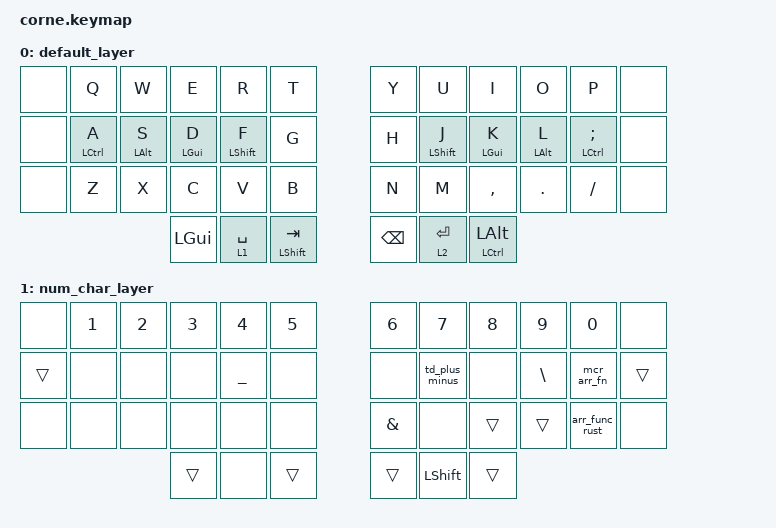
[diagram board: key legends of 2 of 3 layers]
/*
 * Copyright (c) 2020 The ZMK Contributors
 *
 * SPDX-License-Identifier: MIT
 */

#include <behaviors.dtsi>
#include <dt-bindings/zmk/bt.h>
#include <dt-bindings/zmk/keys.h>

&soft_off { hold-time-ms = <200>; };

/ {
    macros {
        mcr_arr_fn: macro_arrow_fn {
            compatible = "zmk,behavior-macro";
            #binding-cells = <0>;
            bindings = <&kp EQUAL &kp GT &kp SPACE &kp LEFT_BRACE &kp RET>;
            label = "MACRO_ARROW_FN";
        };

        mcr_comma_space_cyr: mcr_comma_space {
            compatible = "zmk,behavior-macro";
            #binding-cells = <0>;
            bindings = <&kp CARET &kp SPACE>;
            label = "MCR_COMMA_SPACE";
        };

        mcr_dot_space_cyr: mcr_dot_space {
            compatible = "zmk,behavior-macro";
            #binding-cells = <0>;
            bindings = <&kp AMPERSAND &kp SPACE &skl LEFT_SHIFT>;
            label = "MCR_DOT_SPACE";
        };

        mcr_ctrl_c: ctrl_c {
            compatible = "zmk,behavior-macro";
            #binding-cells = <0>;
            bindings = <&kp LG(C)>;
            label = "CTRL_C";
        };

        mcr_ctrl_v: ctrl_v {
            compatible = "zmk,behavior-macro";
            #binding-cells = <0>;
            bindings = <&kp LG(V)>;
            label = "CTRL_V";
        };

        mcr_switch_language: switch_language {
            compatible = "zmk,behavior-macro";
            #binding-cells = <0>;
            bindings = <&kp LC(SPACE)>;
            label = "SWITCH_LANGUAGE";
        };

        mcr_ctrl_z: mcr_ctrl_z {
            compatible = "zmk,behavior-macro";
            #binding-cells = <0>;
            bindings = <&kp LG(Z)>;
            label = "MCR_CTRL_Z";
        };

        mcr_ctrl_a: mcr_ctrl_a {
            compatible = "zmk,behavior-macro";
            #binding-cells = <0>;
            bindings = <&kp LG(A)>;
            label = "MCR_CTRL_A";
        };

        mcr_fullsize_window: mcr_fullsize_window {
            compatible = "zmk,behavior-macro";
            #binding-cells = <0>;
            bindings = <&kp LG(LC(F))>;
            label = "MCR_FULLSIZE_WINDOW";
        };

        mcr_switch_window_right: mcr_switch_window_right {
            compatible = "zmk,behavior-macro";
            #binding-cells = <0>;
            bindings = <&kp LC(RIGHT)>;
            label = "MCR_SWITCH_WINDOW_RIGHT";
        };

        mcr_switch_window_left: mcr_switch_window_left {
            compatible = "zmk,behavior-macro";
            #binding-cells = <0>;
            bindings = <&kp LC(LEFT)>;
            label = "MCR_SWITCH_WINDOW_LEFT";
        };

        mcr_view_all_windows: mcr_view_all_windows {
            compatible = "zmk,behavior-macro";
            #binding-cells = <0>;
            bindings = <&kp LC(UP_ARROW)>;
            label = "MCR_VIEW_ALL_WINDOWS";
        };

        mcr_screenshot: mcr_screenshot {
            compatible = "zmk,behavior-macro";
            #binding-cells = <0>;
            bindings = <&kp LG(LS(NUMBER_4))>;
            label = "MCR_SCREENSHOT";
        };

        mcr_video: mcr_video {
            compatible = "zmk,behavior-macro";
            #binding-cells = <0>;
            bindings = <&kp LG(LS(N5))>;
            label = "MCR_VIDEO";
        };

        arr_func_rust: arr_func_rust {
            compatible = "zmk,behavior-macro";
            #binding-cells = <0>;
            bindings = <&kp MINUS &kp GT &kp SPACE>;
            label = "ARR_FUNC_RUST";
        };
    };

    combos {
        compatible = "zmk,combos";

        esc {
            bindings = <&kp ESC>;
            key-positions = <16 15>;
        };

        softoff {
            bindings = <&soft_off>;
            key-positions = <36 25>;
        };

        single_quote_combo {
            bindings = <&td_quotes>;
            key-positions = <6 18>;
        };

        right_esc {
            bindings = <&kp ESC>;
            key-positions = <20 19>;
        };

        caps_lock {
            bindings = <&kp CAPSLOCK>;
            key-positions = <2 3 4>;
        };

        switch_language {
            bindings = <&mcr_switch_language>;
            key-positions = <38 39>;
        };

        left_bracket {
            bindings = <&kp LEFT_BRACKET>;
            key-positions = <2 14>;
        };

        right_bracket {
            bindings = <&kp RIGHT_BRACKET>;
            key-positions = <21 9>;
        };

        left_brace {
            bindings = <&kp LEFT_BRACE>;
            key-positions = <3 15>;
        };

        right_brace {
            bindings = <&kp RIGHT_BRACE>;
            key-positions = <8 20>;
        };

        lapr {
            bindings = <&kp LEFT_PARENTHESIS>;
            key-positions = <4 16>;
        };

        rapr {
            bindings = <&kp RIGHT_PARENTHESIS>;
            key-positions = <7 19>;
        };

        eaqual {
            bindings = <&td_equal__>;
            key-positions = <5 17>;
        };

        tilda_grave {
            bindings = <&td_tilda_grave>;
            key-positions = <1 13>;
        };

        ble_reset {
            bindings = <&bt BT_CLR_ALL>;
            key-positions = <1 36>;
        };
    };

    behaviors {
        hrm: homerow_mods {
            compatible = "zmk,behavior-hold-tap";
            label = "HOMEROW_MODS";
            #binding-cells = <2>;
            flavor = "tap-preferred";
            tapping-term-ms = <225>;
            quick-tap-ms = <195>;
            global-quick-tap;
            bindings = <&kp>, <&kp>;
        };

        td_star_hash: td_star_hash {
            compatible = "zmk,behavior-tap-dance";
            label = "TD_STAR_HASH";
            #binding-cells = <0>;
            bindings = <&kp ASTERISK>, <&kp HASH>;

            tapping-term-ms = <260>;
        };

        skl: sticky_key_long_release {
            compatible = "zmk,behavior-sticky-key";
            label = "STICKY_KEY_LONG_RELEASE";
            bindings = <&kp>;
            #binding-cells = <1>;
            release-after-ms = <5000>;
            ignore-modifiers;
            quick-release;
        };

        td_quotes: td_quotes {
            compatible = "zmk,behavior-tap-dance";
            label = "TD_QUOTES";
            #binding-cells = <0>;
            bindings = <&kp SINGLE_QUOTE>, <&kp DOUBLE_QUOTES>;
        };

        td_tilda_grave: td_tilda_grave {
            compatible = "zmk,behavior-tap-dance";
            label = "TD_TILDA_GRAVE";
            #binding-cells = <0>;
            bindings = <&kp GRAVE>, <&kp TILDE>;
        };

        td_plus_minus: td_plus_minus {
            compatible = "zmk,behavior-tap-dance";
            label = "TD_PLUS_MINUS";
            #binding-cells = <0>;
            bindings = <&kp PLUS>, <&kp MINUS>;
        };

        td_equal__: td_equal__ {
            compatible = "zmk,behavior-tap-dance";
            label = "TD_EQUAL__";
            #binding-cells = <0>;
            bindings = <&kp EQUAL>, <&kp UNDERSCORE>;
        };
    };

    keymap {
        compatible = "zmk,keymap";

        default_layer {
            // -----------------------------------------------------------------------------------------
            // |  TAB |  Q  |  W  |  E  |  R  |  T  |   |  Y  |  U   |  I  |  O  |  P  | BKSP |
            // | CTRL |  A  |  S  |  D  |  F  |  G  |   |  H  |  J   |  K  |  L  |  ;  |  '   |
            // | SHFT |  Z  |  X  |  C  |  V  |  B  |   |  N  |  M   |  ,  |  .  |  /  | ESC  |
            //                    | GUI | LWR | SPC |   | ENT | RSE  | ALT |

            bindings = <
&none  &kp Q                &kp W            &kp E            &kp R              &kp T                 &kp Y          &kp U              &kp I                      &kp O            &kp P                   &none
&none  &hrm LEFT_CONTROL A  &hrm LEFT_ALT S  &hrm LEFT_GUI D  &hrm LEFT_SHIFT F  &kp G                 &kp H          &hrm LEFT_SHIFT J  &hrm LEFT_GUI K            &hrm LEFT_ALT L  &hrm LEFT_CONTROL SEMI  &none
&none  &kp Z                &kp X            &kp C            &kp V              &kp B                 &kp N          &kp M              &kp COMMA                  &kp DOT          &kp FSLH                &none
                                             &kp LGUI         &lt 1 SPACE        &mt LEFT_SHIFT TAB    &kp BACKSPACE  &lt 2 ENTER        &mt LEFT_CONTROL LEFT_ALT
            >;
        };

        num_char_layer {
            bindings = <
&none   &kp NUMBER_1  &kp NUMBER_2  &kp N3  &kp NUMBER_4  &kp N5    &kp N6         &kp N7          &kp N8  &kp N9         &kp N0          &none
&trans  &none         &none         &none   &kp UNDER     &none     &none          &td_plus_minus  &none   &kp BACKSLASH  &mcr_arr_fn     &trans
&none   &none         &none         &none   &none         &none     &kp AMPERSAND  &none           &trans  &trans         &arr_func_rust  &none
                                    &trans  &none         &trans    &trans         &kp LEFT_SHIFT  &trans
            >;
        };

        func_layer {
            bindings = <
&none  &none       &kp C_BRIGHTNESS_DEC  &kp C_BRIGHTNESS_INC  &none  &none      &none           &none                  &none                    &none                     &mcr_screenshot  &none
&none  &kp C_PREV  &kp C_PP              &kp C_NEXT            &none  &kp F12    &kp LEFT_ARROW  &kp DOWN               &kp UP_ARROW             &kp RIGHT_ARROW           &mcr_video       &none
&none  &kp K_MUTE  &kp C_VOLUME_DOWN     &kp C_VOLUME_UP       &none  &none      &none           &mcr_view_all_windows  &mcr_switch_window_left  &mcr_switch_window_right  &none            &trans
                                         &none                 &none  &none      &none           &none
            >;
        };
    };
};
